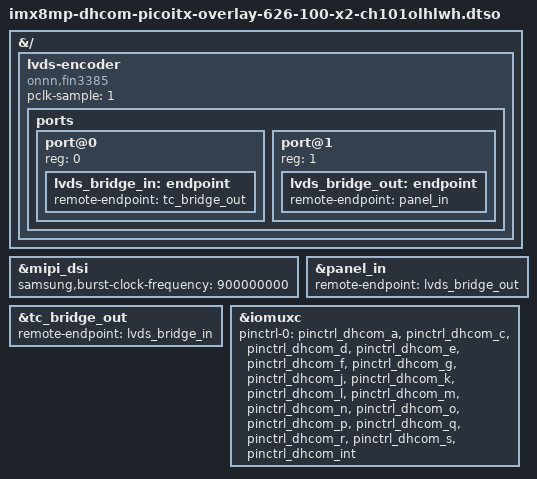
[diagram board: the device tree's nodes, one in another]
// SPDX-License-Identifier: (GPL-2.0+ OR MIT)
/*
 * Copyright (C) 2024-2026 Marek Vasut
 */
/dts-v1/;
/plugin/;

#define DH_OVERLAY_PANEL_I2C_BUS			i2c5
#define DH_OVERLAY_PANEL_I2C_TOUCHSCREEN_PINCTRL	&pinctrl_dhcom_b &pinctrl_dhcom_h
/* GPIO C - X21 */
#define DH_OVERLAY_PANEL_I2C_TOUCHSCREEN_IRQ_PARENT	gpio1
#define DH_OVERLAY_PANEL_I2C_TOUCHSCREEN_IRQ_PIN	11
/* GPIO B - X25 */
#define DH_OVERLAY_PANEL_I2C_TOUCHSCREEN_RESET_GPIO	gpio1
#define DH_OVERLAY_PANEL_I2C_TOUCHSCREEN_RESET_PIN	8

#include "imx8mp-dhcom-overlay-panel-dpi.dtsi"
#include "imx8mp-dhcom-overlay-panel-ch101olhlwh.dtsi"
#include "imx8mp-pinfunc.h"

&{/} {
	lvds-encoder {
		compatible = "onnn,fin3385", "lvds-encoder";
		pclk-sample = <1>;

		ports {
			#address-cells = <1>;
			#size-cells = <0>;

			port@0 {
				reg = <0>;

				lvds_bridge_in: endpoint {
					remote-endpoint = <&tc_bridge_out>;
				};
			};

			port@1 {
				reg = <1>;

				lvds_bridge_out: endpoint {
					remote-endpoint = <&panel_in>;
				};
			};
		};
	};
};

&mipi_dsi {
	/*
	 * This is DSIM PLL frequency, DSI HS clock lane frequency
	 * is half of the "samsung,burst-clock-frequency" value.
	 */
	samsung,burst-clock-frequency = <900000000>;
};

&panel_in {
	remote-endpoint = <&lvds_bridge_out>;
};

&tc_bridge_out {
	remote-endpoint = <&lvds_bridge_in>;
};

&iomuxc {
	/*
	 * The following DHCOM GPIOs are used on this board.
	 * Therefore, they have been removed from the list below.
	 * B: Touch controller #RESET
	 * H: Touch controller IRQ
	 * I: Yellow led
	 */
	pinctrl-0 = <&pinctrl_dhcom_a &pinctrl_dhcom_c &pinctrl_dhcom_d
		     &pinctrl_dhcom_e &pinctrl_dhcom_f &pinctrl_dhcom_g
		     &pinctrl_dhcom_j &pinctrl_dhcom_k &pinctrl_dhcom_l
		     &pinctrl_dhcom_m &pinctrl_dhcom_n &pinctrl_dhcom_o
		     &pinctrl_dhcom_p &pinctrl_dhcom_q &pinctrl_dhcom_r
		     &pinctrl_dhcom_s &pinctrl_dhcom_int>;
};
